# CKGEN_CM_CORE_AON register map
Vendor: Texas Instruments
Peripheral module from a debugger description file (folder omap5430_ES2_PUBLIC).
Registers are 32-bit, access per field, reset values left out (the file's numbers can be read two ways) unless marked. A register's access mark holds for its fields unless they carry their own. Offsets are as the file gives them; lines under a group give offsets from that group; [hi:lo] are bit positions; {n}, {i} and the like mark numbered series; 'fields as' and 'values as' point back to an identical list; <NAME> marks a mode.

## CKGEN_CM_CORE_AON
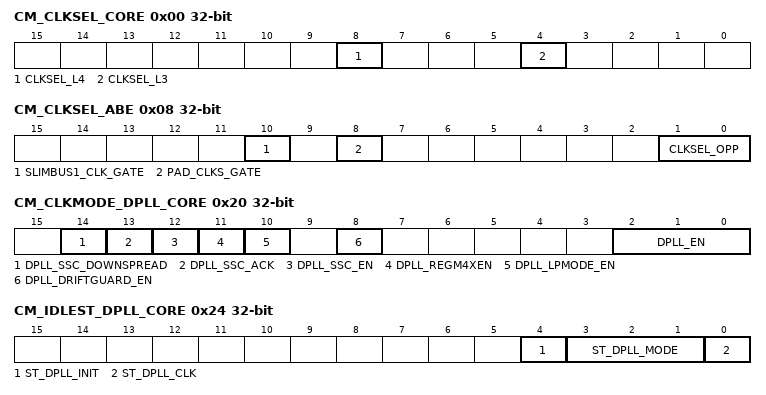
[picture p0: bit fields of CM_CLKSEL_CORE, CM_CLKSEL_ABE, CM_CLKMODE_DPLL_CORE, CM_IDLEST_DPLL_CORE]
0x00 CM_CLKSEL_CORE — CORE module clock selection.
  [8] CLKSEL_L4 rw — Selects L4 interconnect clock (L4_CLK)
    0=L3_CLK_DIV_1 (L4_CLK is L3_CLK divided by 1); 1=L3_CLK_DIV_2 (L4_CLK is L3_CLK divided by 2, to be used for both OPP_NOM and OPP_LOW)
  [4] CLKSEL_L3 rw — Selects L3 interconnect clock (L3_CLK)
    0=CORE_CLK_DIV_1 (L3_CLK is CORE_CLK divided by 1); 1=CORE_CLK_DIV_2 (L3_CLK is CORE_CLK divided by 2, to be used for both OPP_NOM and OPP_LOW)
0x08 CM_CLKSEL_ABE — ABE module clock selection.
  [10] SLIMBUS1_CLK_GATE rw — Gating control for SLIMBUS_CLK clock tree in ABE.
    0=GATED (The clock is gated); 1=ENABLED (The clock is enabled)
  [8] PAD_CLKS_GATE rw — Gating control for PAD_CLKS clock tree in ABE
    values as SLIMBUS1_CLK_GATE
  [1:0] CLKSEL_OPP rw — Selects the OPP divider ABE domain
    0=DIV_1 (ABE_CLK is divide by 1 of DPLL_ABE_X2_CLK, to be used for OPP_NOM); 1=DIV_2 (ABE_CLK is divide by 2 of DPLL_ABE_X2_CLK, to be used for OPP_LOW); 2=DIV_4 (ABE_CLK is divide by 4 of DPLL_ABE_X2_CLK)
0x10 CM_DLL_CTRL — Special register for DLL control
  [0] DLL_OVERRIDE rw — Control if DLL lock and code outputs are overriden or not
    0=no_ovr (Lock and code outputs are not overriden); 1=ovr (Lock output is overriden to '1' and code output is overriden with a value coming from control module.)
0x20 CM_CLKMODE_DPLL_CORE — This register allows controlling the DPLL modes.
  [14] DPLL_SSC_DOWNSPREAD rw — Control if only low frequency spread is required
    0=FULL_SPREAD (When SSC is enabled, clock frequency is spread on both sides of the programmed frequency); 1=LOW_SPREAD (When SSC is enabled, clock frequency is spread only on the lower side of the programmed frequency)
  [13] DPLL_SSC_ACK ro — Acknowledgement from the DPLL regarding start and stop of Spread Spectrum Clocking feature
    0=Disabled (SSC has been turned off on PLL o/ps); 1=Enabled (SSC has been turned on on PLL o/ps)
  [12] DPLL_SSC_EN rw — Enable or disable Spread Spectrum Clocking
    0=Disabled (SSC disabled); 1=Enabled (SSC enabled)
  [11] DPLL_REGM4XEN ro — Enable the REGM4XEN mode of the DPLL.
    0=DISABLED (REGM4XEN mode of the DPLL is disabled)
  [10] DPLL_LPMODE_EN rw — Set the DPLL in Low Power mode. Check the DPLL documentation to see when this can be enabled.
    0=DISABLED (Low power mode of the DPLL is disabled); 1=ENABLED (Low power mode of the DPLL is enabled)
  [8] DPLL_DRIFTGUARD_EN rw — This bit allows to enable or disable the automatic recalibration feature of the DPLL. The DPLL will automatically start a recalibration process upon assertion of the DPLL's RECAL flag if this bit is set.
    0=Diasbled (DRIFTGUARD feature is disabled); 1=Enabled (DRIFTGUARD feature is enabled)
  [2:0] DPLL_EN rw — DPLL control
    5=DPLL_LP_BYP_MODE (Put the DPLL in Idle Bypass Low Power mode.); 6=DPLL_FR_BYP_MODE (Put the DPLL in Idle Bypass Fast Relock mode.); 7=DPLL_LOCK_MODE (Enables the DPLL in Lock mode)
0x24 CM_IDLEST_DPLL_CORE ro — This register allows monitoring DPLL activity. This register is read only and automatically updated. [warm reset insensitive]
  [4] ST_DPLL_INIT — DPLL init status (for debug purpose)
    1=DPLL_INIT (DPLL has been init); 0=DPLL_NOTINIT (DPLL is not init)
  [3:1] ST_DPLL_MODE — DPLL mode status (for debug purpose)
    0=Transient state. From reset to any LP (low power) idle state or from any power state to any power state (Power states are Low Power Stop mode, Fast Relock Stop mode, Idle Bypass Low Power mode and Idle Bypass Fast Relock mode).; 1=LP_STOP (The DPLL is in Low Power Stop mode); 2=FR_STOP (The DPLL is in Fast Relock Stop mode); 5=LP_BYP (The DPLL is in Idle Bypass Low Power mode); 6=FR_BYP (The DPLL is in Idle Bypass Fast Relock mode)
  [0] ST_DPLL_CLK — DPLL lock status
    1=DPLL_LOCKED (DPLL is LOCKED); 0=DPLL_UNLOCKED (DPLL is either in bypass mode or in stop mode.)
0x28 CM_AUTOIDLE_DPLL_CORE — This register provides automatic control over the DPLL activity.
  [2:0] AUTO_DPLL_MODE rw — DPLL automatic control.
    0=AUTO_CTL_DISABLE (DPLL auto control disabled); 1=AUTO_LP_STOP (The DPLL is automatically put in Low Power Stop mode when its DPLL generated clocks are not required anymore. It is also restarted automatically.); 2=AUTO_FR_STOP (The DPLL is automatically put in Fast Relock Stop mode when its DPLL generated clocks are not required anymore. It is also restarted automatically.); 5=AUTO_LP_BYP (The DPLL is automatically put in Idle Bypass Low Power mode when its DPLL generated clocks are not required anymore. It is also restarted automatically.); 6=AUTO_FR_BYP (The DPLL is automatically put in Idle Bypass Fast Relock mode when its DPLL generated clocks are not required anymore. It is also restarted automatically.)
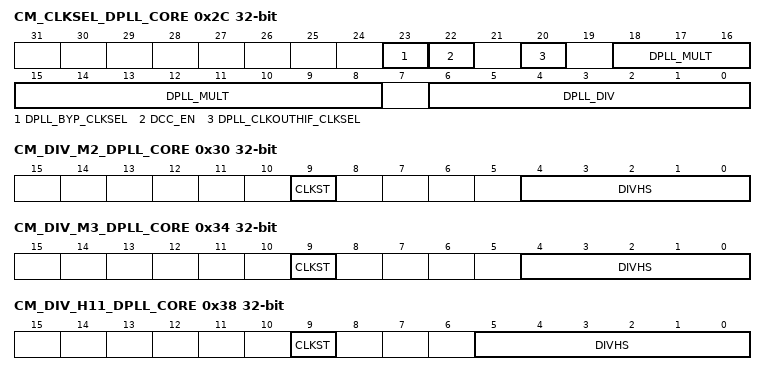
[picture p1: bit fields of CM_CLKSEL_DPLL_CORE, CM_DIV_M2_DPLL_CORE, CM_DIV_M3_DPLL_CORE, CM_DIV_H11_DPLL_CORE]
0x2C CM_CLKSEL_DPLL_CORE — This register provides controls over the DPLL.
  [23] DPLL_BYP_CLKSEL rw — Allows control of the BYPASS clock of the PLL and the associated HSDIVIDER. In DPLL Locked mode: 0 - No impact; 1 - No impact In DPLL Bypass mode: 0x0 - CLKINP is selected as the BYPASS clock for CLKOUT/CLKOUTX2 0x1 - CLKINPULOW is selected as the BYPASS clock for CLKOUT/CLKOUTX2
  [22] DCC_EN ro — Duty-cycle corrector for high frequency clock read 0x0: Duty-cycle corrector is disabled
  [20] DPLL_CLKOUTHIF_CLKSEL rw — Selects the source of the DPLL CLKOUTHIF clock.
    0=SEL_DCO (CLKOUTHIF is generated from the DPLL oscillator (DCO)); 1=SEL_CLKINPHIF (CLKOUTHIF is generated from CLKINPHIF)
  [18:8] DPLL_MULT rw — DPLL multiplier factor (2 to 2047). Equal to input M of DPLL; M=2 to 2047 = DPLL multiplies by M. [warm reset insensitive]
  [6:0] DPLL_DIV rw — DPLL divider factor (0 to 127) (equal to input N of DPLL; actual division factor is N+1). [warm reset insensitive]
0x30 CM_DIV_M2_DPLL_CORE — This register provides controls over the M2 divider of the DPLL.
  [9] CLKST ro — DPLL CLKOUT status
    0=CLK_GATED (The clock output is gated); 1=CLK_ENABLED (The clock output is enabled)
  [4:0] DIVHS rw — DPLL post-divider factor, M2, for internal clock generation (1 to 31); Divide value from 1 to 31.
    2=2,_to_be_used_for_OPP_NOM; 4=Reserved (4, to be used for OPP_LOW)
0x34 CM_DIV_M3_DPLL_CORE — This register provides controls over the M3 divider of the DPLL.
  [9] CLKST ro — DPLL CLKOUTHIF status
    values as CM_DIV_M2_DPLL_CORE.CLKST
  [4:0] DIVHS rw — DPLL M3 post-divider factor (1 to 31).
    5=5,_to_be_used_for_OPP_NOM; 8=8,_to_be_used_for_OPP_LOW
0x38 CM_DIV_H11_DPLL_CORE — This register provides controls over the CLKOUT1 o/p of the HSDIVIDER1.
  [9] CLKST ro — HSDIVIDER1 CLKOUT1 status
    values as CM_DIV_M2_DPLL_CORE.CLKST
  [5:0] DIVHS rw — DPLL (H11+1) post-divider factor (1 to 63).
    8=Reserved (8, to be used for both OPP_NOM and OPP_LOW)
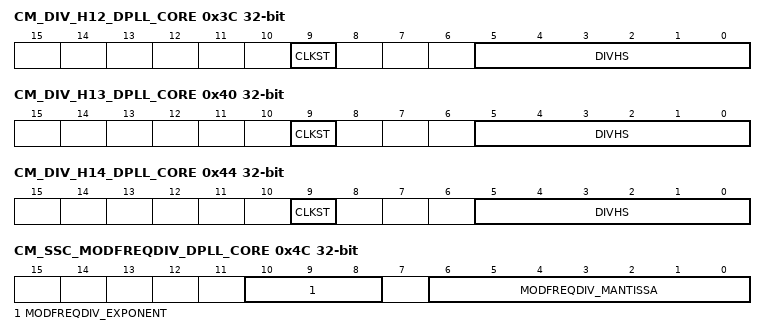
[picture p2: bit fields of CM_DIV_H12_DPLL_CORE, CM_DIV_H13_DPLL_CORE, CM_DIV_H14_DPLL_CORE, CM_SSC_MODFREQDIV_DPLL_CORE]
0x3C CM_DIV_H12_DPLL_CORE — This register provides controls over the CLKOUT2 o/p of the HSDIVIDER1.
  [9] CLKST ro — HSDIVIDER1 CLKOUT2 status
    values as CM_DIV_M2_DPLL_CORE.CLKST
  [5:0] DIVHS rw — DPLL (H12+1) post-divider factor (1 to 63).
    4=4,_to_be_used_for_OPP_NOM; 8=Reserved (8, to be used for OPP_LOW)
0x40 CM_DIV_H13_DPLL_CORE — This register provides controls over the CLKOUT3 o/p of the HSDIVIDER1.
  [9] CLKST ro — HSDIVIDER1 CLKOUT3 status
    values as CM_DIV_M2_DPLL_CORE.CLKST
  [5:0] DIVHS rw — DPLL (H13+1) post-divider factor (1 to 63).
    62=Reserved (62, to be used for both OPP_NOM and OPP_LOW)
0x44 CM_DIV_H14_DPLL_CORE — This register provides controls over the CLKOUT4 o/p of the HSDIVIDER1.
  [9] CLKST ro — HSDIVIDER1 CLKOUT4 status
    values as CM_DIV_M2_DPLL_CORE.CLKST
  [5:0] DIVHS rw — DPLL (H14+1) post-divider factor (1 to 63). When a value of 63 is programmed in this register, HSdivider will perform division by 2.5 that is divided by 2 at top level
0x48 CM_SSC_DELTAMSTEP_DPLL_CORE — Control the DeltaMStep parameter for Spread Spectrum Clocking. [warm reset insensitive]
  [19:0] DELTAMSTEP rw — DeltaMStep is split into fractional and integer part. For Triangular Spread Spectrum: [19:18] for integer part, [17:0] for fractional part For Square Wave Spread Spectrum [19:14] for integer part, [13:0] for fractional part
0x4C CM_SSC_MODFREQDIV_DPLL_CORE — Control the Modulation Frequency (Fm) for Spread Spectrum. [warm reset insensitive]
  [10:8] MODFREQDIV_EXPONENT rw — Set the Exponent component of MODFREQDIV factor
  [6:0] MODFREQDIV_MANTISSA rw — Set the Mantissa component of MODFREQDIV factor
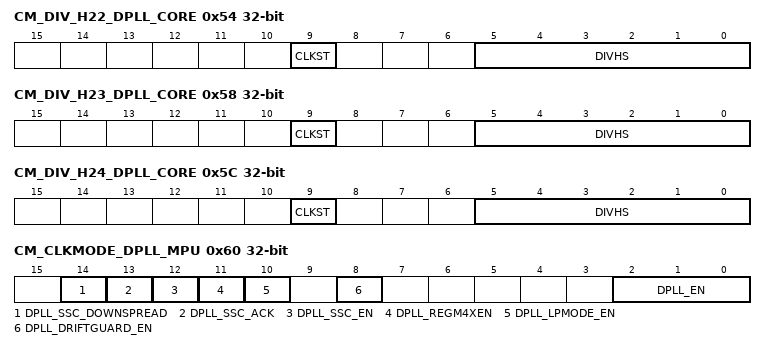
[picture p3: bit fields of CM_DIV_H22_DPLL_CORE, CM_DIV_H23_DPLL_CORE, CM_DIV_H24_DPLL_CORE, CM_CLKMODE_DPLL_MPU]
0x54 CM_DIV_H22_DPLL_CORE — This register provides controls over the CLKOUT2 o/p of the HSDIVIDER2
  [9] CLKST ro — HSDIVIDER2 CLKOUT2 status
    values as CM_DIV_M2_DPLL_CORE.CLKST
  [5:0] DIVHS rw — DPLL (H22+1) post-divider factor (1 to 63).
    5=5,_to_be_used_for_OPP_NOM; 10=Reserved (10, to be used for OPP_LOW)
0x58 CM_DIV_H23_DPLL_CORE — This register provides controls over the CLKOUT3 o/p of the HSDIVIDER2
  [9] CLKST ro — HSDIVIDER2 CLKOUT3 status
    values as CM_DIV_M2_DPLL_CORE.CLKST
  [5:0] DIVHS rw — DPLL (H23+1) post-divider factor (1 to 63).
    7=7,_to_be_used_for_OPP_NOM; 14=Reserved (14, to be used for OPP_LOW)
0x5C CM_DIV_H24_DPLL_CORE — This register provides controls over the CLKOUT4 o/p of the 2nd HSDIVIDER.
  [9] CLKST ro — HSDIVIDER2 CLKOUT4 status
    1=CLK_ENABLED (The clock output is enabled); 0=CLK_GATED (The clock output is gated)
  [5:0] DIVHS rw — DPLL (H24+1) post-divider factor (1 to 63).
0x60 CM_CLKMODE_DPLL_MPU — This register allows controlling the DPLL modes.
  fields as CM_CLKMODE_DPLL_CORE
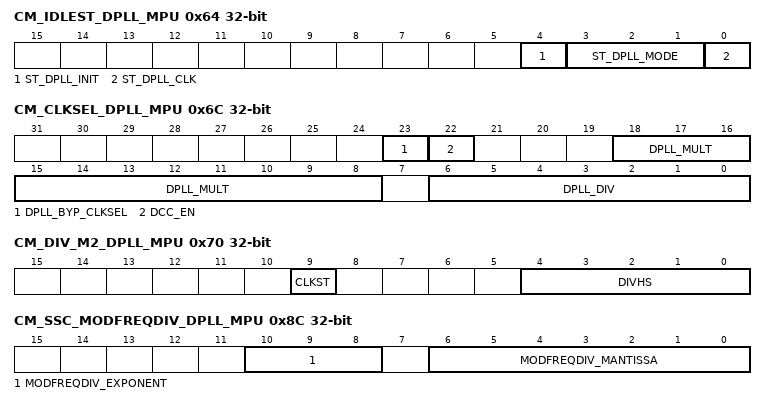
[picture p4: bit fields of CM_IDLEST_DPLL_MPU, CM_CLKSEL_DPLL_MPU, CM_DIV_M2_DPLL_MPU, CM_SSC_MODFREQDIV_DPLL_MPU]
0x64 CM_IDLEST_DPLL_MPU ro — This register allows monitoring DPLL activity. This register is read only and automatically updated. [warm reset insensitive]
  [4] ST_DPLL_INIT — DPLL init status (for debug purpose)
    values as CM_IDLEST_DPLL_CORE.ST_DPLL_INIT
  [3:1] ST_DPLL_MODE — DPLL mode status (for debug purpose)
    0=Transient state. From reset to any LP (low power) idle state or from any power state to any power state (Power states are Low Power Stop mode, Fast Relock Stop mode, Idle Bypass Low Power mode and Idle Bypass Fast Relock mode).; 1=LP_STOP (The DPLL is in Low Power Stop mode.); 2=FR_STOP (The DPLL is in Fast Relock Stop mode.); 5=LP_BYP (The DPLL is in Idle Bypass Low Power mode.); 6=FR_BYP (The DPLL is in Idle Bypass Fast Relock mode)
  [0] ST_DPLL_CLK — DPLL lock status
    values as CM_IDLEST_DPLL_CORE.ST_DPLL_CLK
0x68 CM_AUTOIDLE_DPLL_MPU — This register provides automatic control over the DPLL activity.
  [2:0] AUTO_DPLL_MODE rw — DPLL automatic control;
    values as CM_AUTOIDLE_DPLL_CORE.AUTO_DPLL_MODE
0x6C CM_CLKSEL_DPLL_MPU — This register provides controls over the DPLL.
  [23] DPLL_BYP_CLKSEL ro — Only CLKINPULOW bypass clock supported for this PLL
  [22] DCC_EN rw — Duty-cycle corrector for high frequency clock 0x0: Duty-cycle corrector is disabled 0x1: Duty-cycle corrector is enabled
  [18:8] DPLL_MULT rw — DPLL multiplier factor (2 to 2047) Equal to input M of DPLL; M=2 to 2047 = DPLL multiplies by M. [warm reset insensitive]
  [6:0] DPLL_DIV rw — DPLL divider factor (0 to 127) (equal to input N of DPLL; actual division factor is N+1). [warm reset insensitive]
0x70 CM_DIV_M2_DPLL_MPU — This register provides controls over the M2 divider of the DPLL.
  [9] CLKST ro — DPLL CLKOUT status
    values as CM_DIV_M2_DPLL_CORE.CLKST
  [4:0] DIVHS rw — DPLL M2 post-divider factor (1 to 31).
    1=OPP_NOM,_OPP_HIGH_OPP_SPEEDBIN_1 (1, to be used for OPP_NOM, OPP_HIGH and OPP_SPEEDBIN); 2=Reserved (2, to be used for OPP_LOW)
0x88 CM_SSC_DELTAMSTEP_DPLL_MPU — Control the DeltaMStep parameter for Spread Spectrum Clocking. [warm reset insensitive]
  fields as CM_SSC_DELTAMSTEP_DPLL_CORE
0x8C CM_SSC_MODFREQDIV_DPLL_MPU — Control the Modulation Frequency (Fm) for Spread Spectrum. [warm reset insensitive]
  fields as CM_SSC_MODFREQDIV_DPLL_CORE
0x9C CM_BYPCLK_DPLL_MPU — Control MPU PLL BYPASS clock. [warm reset insensitive]
  [1:0] CLKSEL rw — Select the DPLL MPU bypass clock
    0=CORE_X2_CLK_DIV_1 (DPLL_MPU bypass clock is CORE_X2_CLK divided by 1, to be used for both OPP_NOM and OPP_LOW); 1=CORE_X2_CLK_DIV_2 (DPLL_MPU bypass clock is CORE_X2_CLK divided by 2); 2=CORE_X2_CLK_DIV_4 (DPLL_MPU bypass clock is CORE_X2_CLK divided by 4); 3=CORE_X2_CLK_DIV_8 (DPLL_MPU bypass clock is CORE_X2_CLK divided by 8)
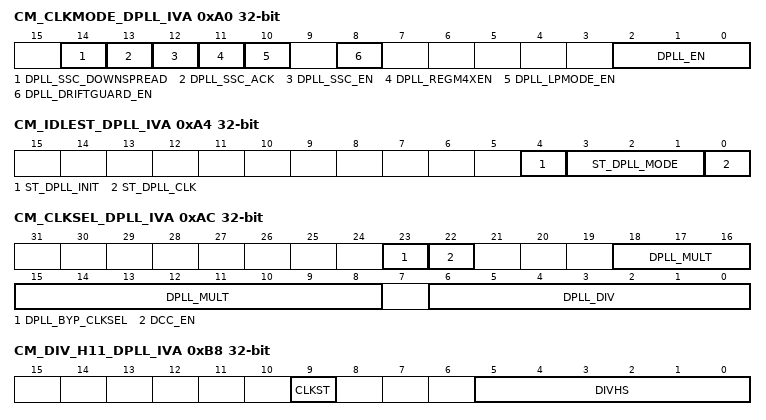
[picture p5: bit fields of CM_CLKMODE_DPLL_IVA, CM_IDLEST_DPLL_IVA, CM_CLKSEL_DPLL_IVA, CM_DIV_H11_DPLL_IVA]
0xA0 CM_CLKMODE_DPLL_IVA — This register allows controlling the DPLL modes.
  [14] DPLL_SSC_DOWNSPREAD rw — Control if only low frequency spread is required
    values as CM_CLKMODE_DPLL_CORE.DPLL_SSC_DOWNSPREAD
  [13] DPLL_SSC_ACK ro — Acknowledgement from the DPLL regarding start and stop of Spread Spectrum Clocking feature
    values as CM_CLKMODE_DPLL_CORE.DPLL_SSC_ACK
  [12] DPLL_SSC_EN rw — Enable or disable Spread Spectrum Clocking
    0=Disabled (SSC disabled); 1=Enabled (SSC enabled)
  [11] DPLL_REGM4XEN ro — Enable the REGM4XEN mode of the DPLL.
    0=DISABLED (REGM4XEN mode of the DPLL is disabled)
  [10] DPLL_LPMODE_EN rw — Set the DPLL in Low Power mode. Check the DPLL documentation to see when this can be enabled.
    values as CM_CLKMODE_DPLL_CORE.DPLL_LPMODE_EN
  [8] DPLL_DRIFTGUARD_EN rw — This bit allows to enable or disable the automatic recalibration feature of the DPLL. The DPLL will automatically start a recalibration process upon assertion of the DPLL's RECAL flag if this bit is set.
    values as CM_CLKMODE_DPLL_CORE.DPLL_DRIFTGUARD_EN
  [2:0] DPLL_EN rw — DPLL control
    5=DPLL_LP_BYP_MODE (Put the DPLL in Idle Bypass Low Power mode.); 6=DPLL_FR_BYP_MODE (Put the DPLL in Idle Bypass Fast Relock mode); 7=DPLL_LOCK_MODE (Enables the DPLL in Lock mode)
0xA4 CM_IDLEST_DPLL_IVA ro — This register allows monitoring DPLL activity. This register is read only and automatically updated. [warm reset insensitive]
  [4] ST_DPLL_INIT — DPLL init status (for debug purpose)
    values as CM_IDLEST_DPLL_CORE.ST_DPLL_INIT
  [3:1] ST_DPLL_MODE — DPLL mode status (for debug purpose)
    0=Transient state. From reset to any LP (low power) idle state or from any power state to any power state (Power states are Low Power Stop mode, Fast Relock Stop mode, Idle Bypass Low Power mode and Idle Bypass Fast Relock mode).; 1=LP_STOP (The DPLL is in Low Power Stop mode.); 2=FR_STOP (The DPLL is in Fast Relock Stop mode.); 5=LP_BYP (The DPLL is in Idle Bypass Low Power mode.); 6=FR_BYP (The DPLL is in Idle Bypass Low Power mode.)
  [0] ST_DPLL_CLK — DPLL lock status
    values as CM_IDLEST_DPLL_CORE.ST_DPLL_CLK
0xA8 CM_AUTOIDLE_DPLL_IVA — This register provides automatic control over the DPLL activity.
  fields as CM_AUTOIDLE_DPLL_MPU
0xAC CM_CLKSEL_DPLL_IVA — This register provides controls over the DPLL.
  [23] DPLL_BYP_CLKSEL rw — Allows control of the BYPASS clock of the PLL and the associated HSDIVIDER. In DPLL Locked mode, 0 - No impact 1 - No impact In DPLL Bypass mode, 0 - CLKINP is selected as the BYPASS clock for CLKOUT/CLKOUTX2 1 - CLKINPULOW is selected as the BYPASS clock for CLKOUT/CLKOUTX2
  [22] DCC_EN ro — Duty-cycle corrector for high frequency clock Read 0: Duty-cycle corrector is disabled
  [18:8] DPLL_MULT rw — DPLL multiplier factor (2 to 2047). Equal to input M of DPLL; M=2 to 2047 = DPLL multiplies by M). [warm reset insensitive]
  [6:0] DPLL_DIV rw — DPLL divider factor (0 to 127) (equal to input N of DPLL; actual division factor is N+1). [warm reset insensitive]
0xB8 CM_DIV_H11_DPLL_IVA — This register provides controls over the CLKOUT1 o/p of the HSDIVIDER1.
  [9] CLKST ro — HSDIVIDER1 CLKOUT1 status
    values as CM_DIV_M2_DPLL_CORE.CLKST
  [5:0] DIVHS rw — DPLL (H11+1) post-divider factor (1 to 63).
    2=2,_to_be_used_for_OPP_OD; 5=5,_to_be_used_for_OPP_NOM; 10=Reserved (10, to be used for OPP_LOW)
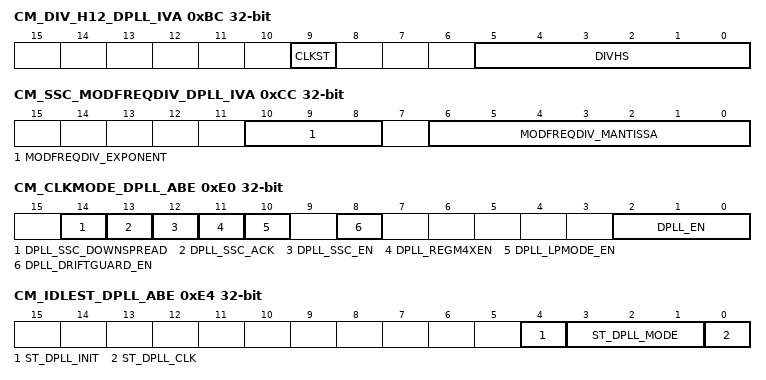
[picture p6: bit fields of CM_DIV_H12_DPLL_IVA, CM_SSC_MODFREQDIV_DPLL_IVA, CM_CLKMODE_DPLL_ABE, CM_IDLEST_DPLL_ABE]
0xBC CM_DIV_H12_DPLL_IVA — This register provides controls over the CLKOUT2 o/p of the HSDIVIDER1.
  [9] CLKST ro — HSDIVIDER1 CLKOUT2 status
    values as CM_DIV_M2_DPLL_CORE.CLKST
  [5:0] DIVHS rw — DPLL (H12+1) post-divider factor (1 to 31).
    2=2,_to_be_used_for_OPP_OD; 6=6,_to_be_used_for_OPP_NOM; 12=Reserved (12, to be used for OPP_LOW)
0xC8 CM_SSC_DELTAMSTEP_DPLL_IVA — Control the DeltaMStep parameter for Spread Spectrum Clocking. [warm reset insensitive]
  fields as CM_SSC_DELTAMSTEP_DPLL_CORE
0xCC CM_SSC_MODFREQDIV_DPLL_IVA — Control the Modulation Frequency (Fm) for Spread Spectrum. [warm reset insensitive]
  fields as CM_SSC_MODFREQDIV_DPLL_CORE
0xDC CM_BYPCLK_DPLL_IVA — Control IVA PLL BYPASS clock. [warm reset insensitive]
  [1:0] CLKSEL rw — Select the DPLL IVA bypass clock
    0=CORE_X2_CLK_DIV_1 (DPLL_IVA bypass clock is CORE_X2_CLK divided by 1, to be used for both OPP_NOM and OPP_LOW); 1=CORE_X2_CLK_DIV_2 (DPLL_IVA bypass clock is CORE_X2_CLK divided by 2); 2=CORE_X2_CLK_DIV_4 (DPLL_IVA bypass clock is CORE_X2_CLK divided by 4); 3=CORE_X2_CLK_DIV_8 (DPLL_IVA bypass clock is CORE_X2_CLK divided by 8)
0xE0 CM_CLKMODE_DPLL_ABE — This register allows controlling the DPLL modes.
  [14] DPLL_SSC_DOWNSPREAD rw — Control if only low frequency spread is required
    values as CM_CLKMODE_DPLL_CORE.DPLL_SSC_DOWNSPREAD
  [13] DPLL_SSC_ACK ro — Acknowledgement from the DPLL regarding start and stop of Spread Spectrum Clocking feature
    values as CM_CLKMODE_DPLL_CORE.DPLL_SSC_ACK
  [12] DPLL_SSC_EN rw — Enable or disable Spread Spectrum Clocking
    0=Disabled (SSC disabled); 1=Enabled (SSC enabled)
  [11] DPLL_REGM4XEN rw — Enable the REGM4XEN mode of the DPLL.
    0=ENABLE (REGM4XEN mode of the DPLL is disabled 0x1: REGM4XEN mode of the DPLL is enabled)
  [10] DPLL_LPMODE_EN rw — Set the DPLL in Low Power mode. Check the DPLL documentation to see when this can be enabled.
    values as CM_CLKMODE_DPLL_CORE.DPLL_LPMODE_EN
  [8] DPLL_DRIFTGUARD_EN rw — This bit allows to enable or disable the automatic recalibration feature of the DPLL. The DPLL will automatically start a recalibration process upon assertion of the DPLL's RECAL flag if this bit is set.
    values as CM_CLKMODE_DPLL_CORE.DPLL_DRIFTGUARD_EN
  [2:0] DPLL_EN rw — DPLL control
    values as CM_CLKMODE_DPLL_CORE.DPLL_EN
0xE4 CM_IDLEST_DPLL_ABE ro — This register allows monitoring DPLL activity. This register is read only and automatically updated. [warm reset insensitive]
  [4] ST_DPLL_INIT — DPLL init status (for debug purpose)
    0=DPLL_NOTINIT (DPLL is not init); 1=DPLL_INIT (DPLL has been init)
  [3:1] ST_DPLL_MODE — DPLL mode status (for debug purpose)
    values as CM_IDLEST_DPLL_CORE.ST_DPLL_MODE
  [0] ST_DPLL_CLK — DPLL lock status
    values as CM_IDLEST_DPLL_CORE.ST_DPLL_CLK
0xE8 CM_AUTOIDLE_DPLL_ABE — This register provides automatic control over the DPLL activity.
  fields as CM_AUTOIDLE_DPLL_MPU
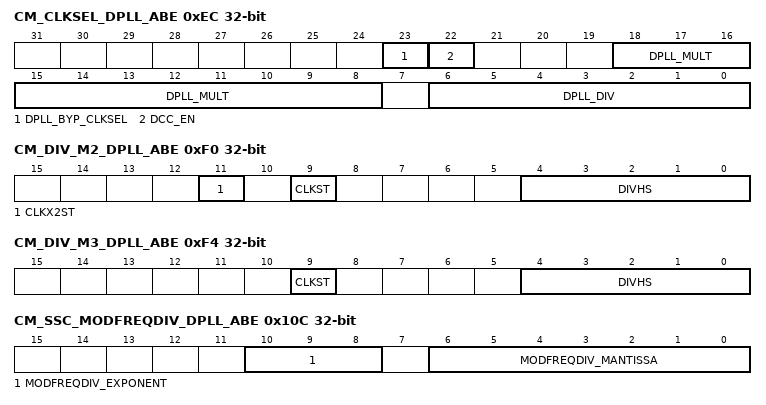
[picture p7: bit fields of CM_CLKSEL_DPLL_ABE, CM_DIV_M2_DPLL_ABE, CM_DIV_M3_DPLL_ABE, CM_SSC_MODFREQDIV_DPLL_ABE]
0xEC CM_CLKSEL_DPLL_ABE — This register provides controls over the DPLL.
  [23] DPLL_BYP_CLKSEL ro — Only CLKINPULOW bypass clock supported for this PLL
  [22] DCC_EN ro — Duty-cycle corrector for high frequency clock Read 0: Duty-cycle corrector is disabled
  [18:8] DPLL_MULT rw — DPLL multiplier factor (2 to 2047). Equal to input M of DPLL; M=2 to 2047 = DPLL multiplies by M [warm reset insensitive]
  [6:0] DPLL_DIV rw — DPLL divider factor (0 to 127) Equal to input N of DPLL, actual division factor is N+1. [warm reset insensitive]
0xF0 CM_DIV_M2_DPLL_ABE — This register provides controls over the M2 divider of the DPLL.
  [11] CLKX2ST ro — DPLL CLKOUTX2 status
    values as CM_DIV_M2_DPLL_CORE.CLKST
  [9] CLKST ro — DPLL CLKOUT status
    values as CM_DIV_M2_DPLL_CORE.CLKST
  [4:0] DIVHS rw — DPLL M2 post-divider factor (1 to 31).
    1=Reserved (1, to be used for both OPP_NOM and OPP_LOW)
0xF4 CM_DIV_M3_DPLL_ABE — This register provides controls over the M3 divider of the DPLL.
  [9] CLKST ro — DPLL CLKOUTHIF status
    values as CM_DIV_M2_DPLL_CORE.CLKST
  [4:0] DIVHS rw — DPLL M3 post-divider factor (1 to 31).
    1=Reserved (1, to be used for both OPP_NOM and OPP_LOW)
0x108 CM_SSC_DELTAMSTEP_DPLL_ABE — Control the DeltaMStep parameter for Spread Spectrum Clocking. [warm reset insensitive]
  fields as CM_SSC_DELTAMSTEP_DPLL_CORE
0x10C CM_SSC_MODFREQDIV_DPLL_ABE — Control the Modulation Frequency (Fm) for Spread Spectrum. [warm reset insensitive]
  fields as CM_SSC_MODFREQDIV_DPLL_CORE
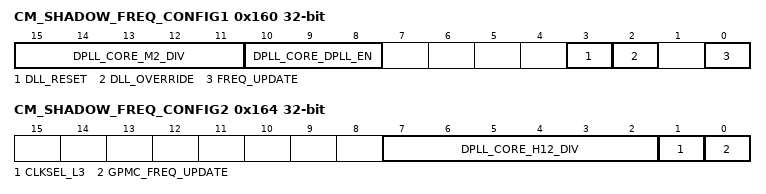
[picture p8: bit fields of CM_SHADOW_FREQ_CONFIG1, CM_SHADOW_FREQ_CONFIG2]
0x160 CM_SHADOW_FREQ_CONFIG1 access not given — Shadow register to program new DPLL configuration affecting EMIF and GPMC (L3 clock) functional frequency during DVFS. The PRCM HW automatically applies the new configuration after EMIF/GPMC have been put in idle state.
  [15:11] DPLL_CORE_M2_DIV rw — Shadow register forCM_DIV_M2_DPLL_CORE[4:0] DIVHS. The main register is automatically loaded with the shadow register value after EMIF IDLE if the FREQ_UPDATE field is set to '1'. Divide value from 1 to 31.
  [10:8] DPLL_CORE_DPLL_EN rw — Shadow register forCM_CLKMODE_DPLL_CORE[2:0] DPLL_EN. The main register is automatically loaded with the shadow register value after EMIF IDLE if the FREQ_UPDATE field is set to '1'.
    values as CM_CLKMODE_DPLL_CORE.DPLL_EN
  [3] DLL_RESET rw — Specify if DLL should be reset or not during the frequency change hardware sequence.
    0=no_reset (DLL is not reset during the frequency change hardware sequence); 1=reset (DLL is reset automatically during the frequency change hardware sequence)
  [2] DLL_OVERRIDE rw — Shadow register forCM_DLL_CTRL[0] DLL_OVERRIDE. The main register is automatically loaded with the shadow register value after EMIF IDLE if the FREQ_UPDATE field is set to '1'.
    values as CM_DLL_CTRL.DLL_OVERRIDE
  [0] FREQ_UPDATE — Writing '1' indicates that a new configuration is available. It is automatically cleared by HW after the configuration has been applied. (access RW WSpecial)
0x164 CM_SHADOW_FREQ_CONFIG2 — Shadow register to program new DPLL configuration affecting GPMC (L3 clock) functional frequency during DVFS. The PRCM HW automatically applies the new configuration after EMIF/GPMC have been put in idle state.
  [7:2] DPLL_CORE_H12_DIV rw — Shadow register forCM_DIV_H12_DPLL_CORE[5:0] DIVHS. The main register is automatically loaded with the shadow register value after GPMC IDLE if the CM_SHADOW_FREQ_CONFIG1[0] FREQ_UPDATE field is set to '1' and GPMC_FREQ_UPDATE is set to '1'. Divide value from 1 to 31.
  [1] CLKSEL_L3 rw — Shadow register forCM_CLKSEL_CORE[4] CLKSEL_L3. The main register is automatically loaded with the shadow register value after GPMC IDLE if the CM_SHADOW_FREQ_CONFIG1[0] FREQ_UPDATE field is set to '1' and GPMC_FREQ_UPDATE is set to '1'.
    0=CORE_CLK_DIV_1 (L3_CLK is CORE_CLK divided by 1); 1=CORE_CLK_DIV_2 (L3_CLK is CORE_CLK divided by 2)
  [0] GPMC_FREQ_UPDATE rw — Controls whether or not GPMC has to be put automatically into idle during the frequency change operation.
    0=Disabled (GPMC is not put automatically into idle during frequency change operation.); 1=Enabled (GPMC is put automatically into idle during frequency change operation.)
0x170 CM_DYN_DEP_PRESCAL — Control the time unit of the sliding window for dynamic dependencies (auto-sleep feature).
  [5:0] PRESCAL rw — Time unit is equal to (PRESCAL + 1) L4 clock cycles.
